# cslr_edmacc_001 register map
Vendor: Texas Instruments
Peripheral module from a debugger description file.
Registers are 32-bit, access not given, reset values left out (the file's numbers can be read two ways) unless marked. A register's access mark holds for its fields unless they carry their own. Offsets are as the file gives them; lines under a group give offsets from that group; [hi:lo] are bit positions; {n}, {i} and the like mark numbered series; 'fields as' and 'values as' point back to an identical list; <NAME> marks a mode.

## EDMACC — Enhanced DMA Channel Controller Module.
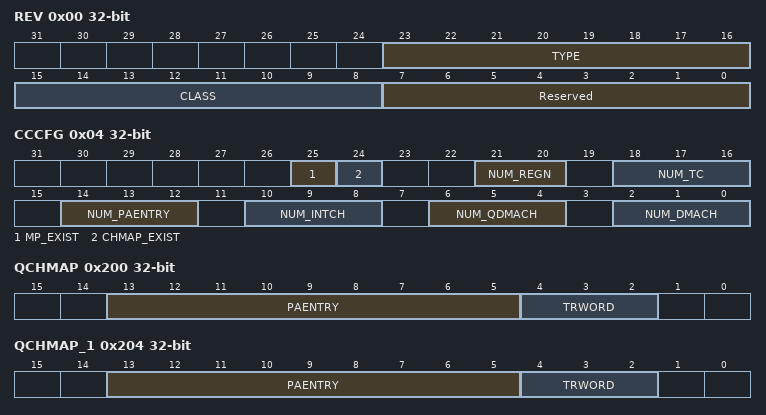
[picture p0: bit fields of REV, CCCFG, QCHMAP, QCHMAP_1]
0x00 REV — Peripheral Revision
  [23:16] TYPE ro — Peripheral Type
  [15:8] CLASS ro — Peripheral Class
  [7:0] Reserved — (access N)
0x04 CCCFG ro — CC Configuration
  [25] MP_EXIST — Memory Protection Existence
    0=None (No Memory protection); 1=INCLUDED (Memory protection logic included)
  [24] CHMAP_EXIST — Channel Mapping Existence
    0=None (No Channel Mapping); 1=INCLUDED (Channel mapping logic included)
  [21:20] NUM_REGN — Number of MP and Shadow regions
    2=4 Regions
  [18:16] NUM_TC — Number of Queues/Number of TCs
    0=1 TC/Event Queue; 1=2 TC/Event Queue
  [14:12] NUM_PAENTRY — Number of PaRAM entries
    3=128 Entries
  [10:8] NUM_INTCH — Number of Interrupt Channels
    1=8 Interrupt Channels; 2=16 Interrupt Channels; 3=32 Interrupt Channels; 4=64 Interrupt Channels
  [6:4] NUM_QDMACH — Number of QDMA Channels
    2=4 QDMA Channels
  [2:0] NUM_DMACH — Number of DMA Channels
    5=64 DMA Channels
0x200 QCHMAP access per field — QDMA Channel Mapping to PaRAM{QCHMAP}
  [13:5] PAENTRY rw — Points to the PaRAM Entry number for the DMA Channel N
  [4:2] TRWORD rw — Points to the specific trigger word of the PaRAM entry defined by PAENTRY
0x204 QCHMAP_1 access per field — QDMA Channel Mapping to PaRAM{QCHMAP}
  fields as QCHMAP
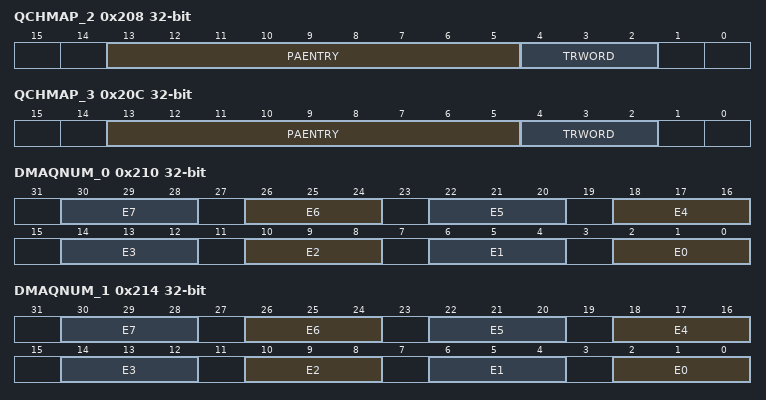
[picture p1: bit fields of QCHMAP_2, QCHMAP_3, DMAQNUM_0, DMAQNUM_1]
0x208 QCHMAP_2 access per field — QDMA Channel Mapping to PaRAM{QCHMAP}
  fields as QCHMAP
0x20C QCHMAP_3 access per field — QDMA Channel Mapping to PaRAM{QCHMAP}
  fields as QCHMAP
0x210 DMAQNUM_0 access per field — DMA Queue Number{DMAQNUM}
  [4n+2:4n] E{n} rw (n=0..7) — Event number = (ArrayIndex * 8) + {n}
0x214 DMAQNUM_1 access per field — DMA Queue Number{DMAQNUM}
  [4n+2:4n] E{n} rw (n=0..7) — Event number = (ArrayIndex * 8) + {n}
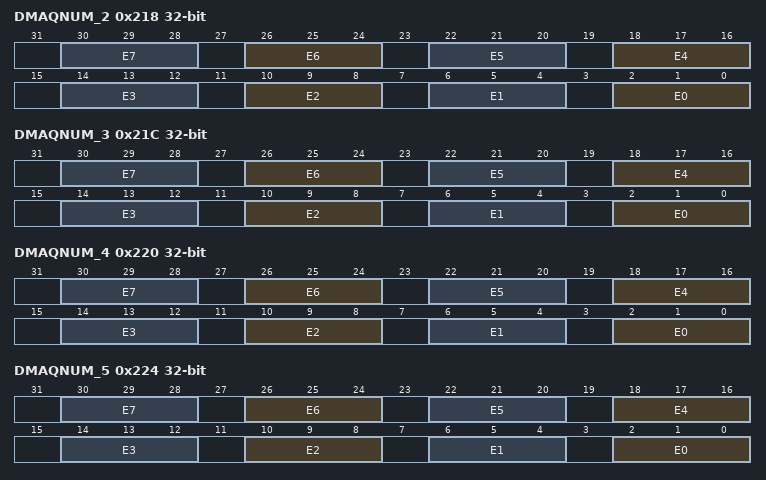
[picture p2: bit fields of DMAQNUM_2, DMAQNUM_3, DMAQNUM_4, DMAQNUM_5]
0x218 DMAQNUM_2 access per field — DMA Queue Number{DMAQNUM}
  [4n+2:4n] E{n} rw (n=0..7) — Event number = (ArrayIndex * 8) + {n}
0x21C DMAQNUM_3 access per field — DMA Queue Number{DMAQNUM}
  [4n+2:4n] E{n} rw (n=0..7) — Event number = (ArrayIndex * 8) + {n}
0x220 DMAQNUM_4 access per field — DMA Queue Number{DMAQNUM}
  [4n+2:4n] E{n} rw (n=0..7) — Event number = (ArrayIndex * 8) + {n}
0x224 DMAQNUM_5 access per field — DMA Queue Number{DMAQNUM}
  [4n+2:4n] E{n} rw (n=0..7) — Event number = (ArrayIndex * 8) + {n}
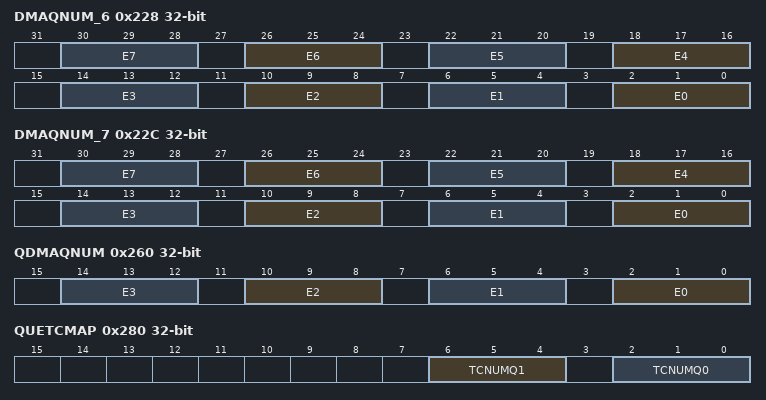
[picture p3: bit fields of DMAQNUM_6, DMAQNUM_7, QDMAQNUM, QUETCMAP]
0x228 DMAQNUM_6 access per field — DMA Queue Number{DMAQNUM}
  [4n+2:4n] E{n} rw (n=0..7) — Event number = (ArrayIndex * 8) + {n}
0x22C DMAQNUM_7 access per field — DMA Queue Number{DMAQNUM}
  [4n+2:4n] E{n} rw (n=0..7) — Event number = (ArrayIndex * 8) + {n}
0x260 QDMAQNUM access per field — QDMA Queue Number
  [4n+2:4n] E{n} rw (n=0..3) — Event number {n}
0x280 QUETCMAP access per field — Queue to TC Mapping
  [6:4] TCNUMQ1 rw — TC Number for Queue 1
  [2:0] TCNUMQ0 rw — TC Number for Queue 0
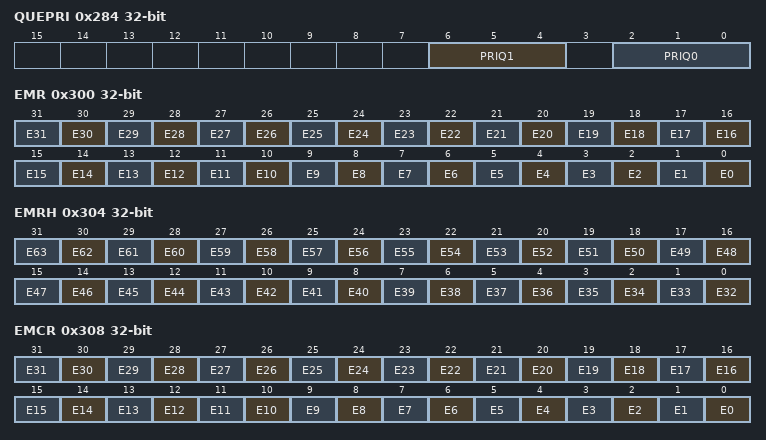
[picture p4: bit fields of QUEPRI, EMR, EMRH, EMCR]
0x284 QUEPRI access per field — Queue Priority
  [6:4] PRIQ1 rw — Priority level for Queue 1
  [2:0] PRIQ0 rw — Priority level for Queue 0
0x300 EMR ro — Event Miss Register
  [n] E{n} (n=0..31) — Event missed number {n}
0x304 EMRH ro — Event Miss Register High
  [n-32] E{n} (n=32..63) — Event missed number {n}
0x308 EMCR ro — Event Miss Clear Register
  [n] E{n} (n=0..31) — Event missed number {n}
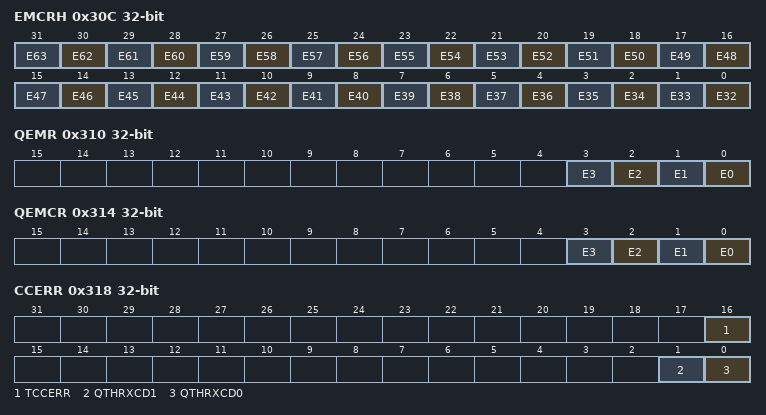
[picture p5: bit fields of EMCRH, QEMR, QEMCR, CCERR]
0x30C EMCRH ro — Event Miss Clear Register High
  [n-32] E{n} (n=32..63) — Event missed number {n}
0x310 QEMR ro — QDMA Event Miss Register
  [n] E{n} (n=0..3) — Event miss event {n}
0x314 QEMCR wo — QDMA Event Miss Register
  [n] E{n} (n=0..3) — Event miss event {n}
0x318 CCERR ro — CC Error Register
  [16] TCCERR — Transfer completion code error
  [1] QTHRXCD1 — Queue Threshold Error for Queue 1
  [0] QTHRXCD0 — Queue Threshold Error for Queue 0
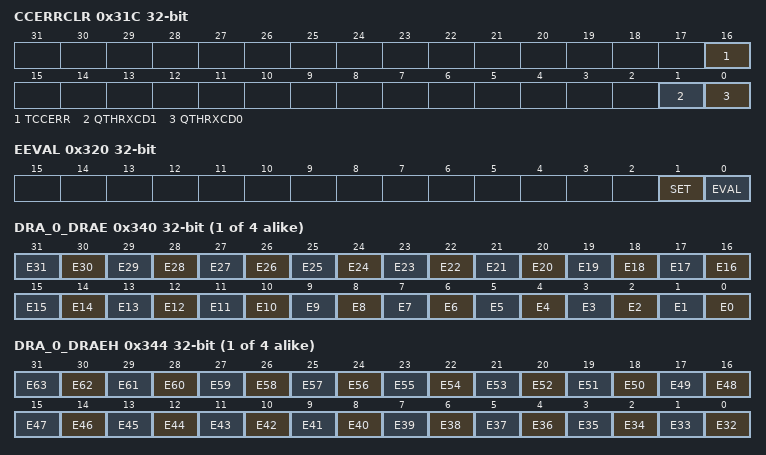
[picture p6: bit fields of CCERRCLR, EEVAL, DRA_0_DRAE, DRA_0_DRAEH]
0x31C CCERRCLR wo — CC Error Clear Register
  fields as CCERR
0x320 EEVAL access per field — Error Evaluation Register
  [1] SET wo — Error interrupt Set
    1=SET (Error Interrupt Set)
  [0] EVAL wo — Error interrupt Evaluate
    1=EVAL (Error Interrupt Evaluate)
{0x340+8i} DRA_{i}_DRAE ro (i=0..3) — DMA Region Access Enable
  [n] E{n} (n=0..31) — Event missed number {n}
{0x344+8i} DRA_{i}_DRAEH ro (i=0..3) — DMA Region Access Enable High
  [n-32] E{n} (n=32..63) — Event missed number {n}
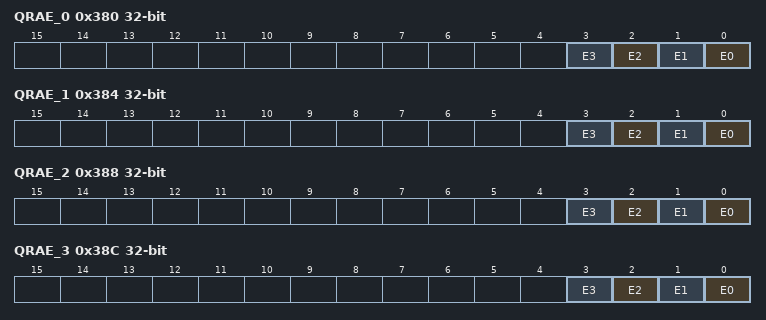
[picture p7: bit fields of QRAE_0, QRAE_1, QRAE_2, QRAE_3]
0x380 QRAE_0 ro — QDMA Region Access Enable{QRAE}
  [n] E{n} (n=0..3) — QDMA Register bit {n}
0x384 QRAE_1 ro — QDMA Region Access Enable{QRAE}
  [n] E{n} (n=0..3) — QDMA Register bit {n}
0x388 QRAE_2 ro — QDMA Region Access Enable{QRAE}
  [n] E{n} (n=0..3) — QDMA Register bit {n}
0x38C QRAE_3 ro — QDMA Region Access Enable{QRAE}
  [n] E{n} (n=0..3) — QDMA Register bit {n}
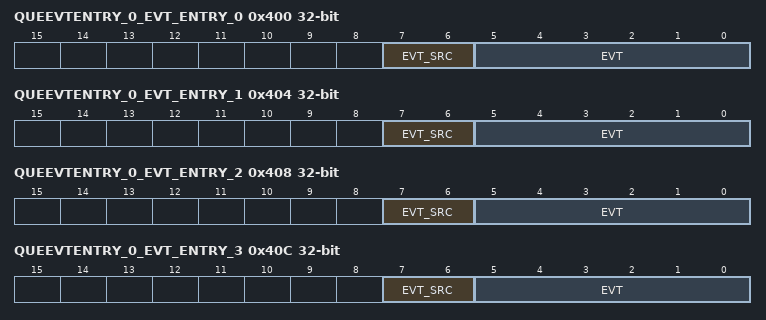
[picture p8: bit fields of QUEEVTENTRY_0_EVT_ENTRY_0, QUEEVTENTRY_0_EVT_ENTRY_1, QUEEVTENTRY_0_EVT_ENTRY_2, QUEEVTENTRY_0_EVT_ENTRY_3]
0x400 QUEEVTENTRY_0_EVT_ENTRY_0 ro — Event Entry{QUEEVTENTRY_0_EVT_ENTRY}
  [7:6] EVT_SRC — Event Source - ER/ESR/CER/QER
  [5:0] EVT — Event
0x404 QUEEVTENTRY_0_EVT_ENTRY_1 ro — Event Entry{QUEEVTENTRY_0_EVT_ENTRY}
  [7:6] EVT_SRC — Event Source - ER/ESR/CER/QER
  [5:0] EVT — Event
0x408 QUEEVTENTRY_0_EVT_ENTRY_2 ro — Event Entry{QUEEVTENTRY_0_EVT_ENTRY}
  [7:6] EVT_SRC — Event Source - ER/ESR/CER/QER
  [5:0] EVT — Event
0x40C QUEEVTENTRY_0_EVT_ENTRY_3 ro — Event Entry{QUEEVTENTRY_0_EVT_ENTRY}
  [7:6] EVT_SRC — Event Source - ER/ESR/CER/QER
  [5:0] EVT — Event
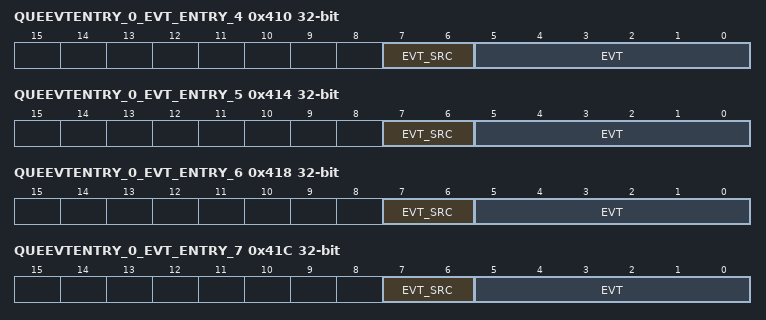
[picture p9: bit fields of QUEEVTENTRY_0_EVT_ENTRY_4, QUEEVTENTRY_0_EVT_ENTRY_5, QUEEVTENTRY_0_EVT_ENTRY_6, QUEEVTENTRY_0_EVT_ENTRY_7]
0x410 QUEEVTENTRY_0_EVT_ENTRY_4 ro — Event Entry{QUEEVTENTRY_0_EVT_ENTRY}
  [7:6] EVT_SRC — Event Source - ER/ESR/CER/QER
  [5:0] EVT — Event
0x414 QUEEVTENTRY_0_EVT_ENTRY_5 ro — Event Entry{QUEEVTENTRY_0_EVT_ENTRY}
  [7:6] EVT_SRC — Event Source - ER/ESR/CER/QER
  [5:0] EVT — Event
0x418 QUEEVTENTRY_0_EVT_ENTRY_6 ro — Event Entry{QUEEVTENTRY_0_EVT_ENTRY}
  [7:6] EVT_SRC — Event Source - ER/ESR/CER/QER
  [5:0] EVT — Event
0x41C QUEEVTENTRY_0_EVT_ENTRY_7 ro — Event Entry{QUEEVTENTRY_0_EVT_ENTRY}
  [7:6] EVT_SRC — Event Source - ER/ESR/CER/QER
  [5:0] EVT — Event
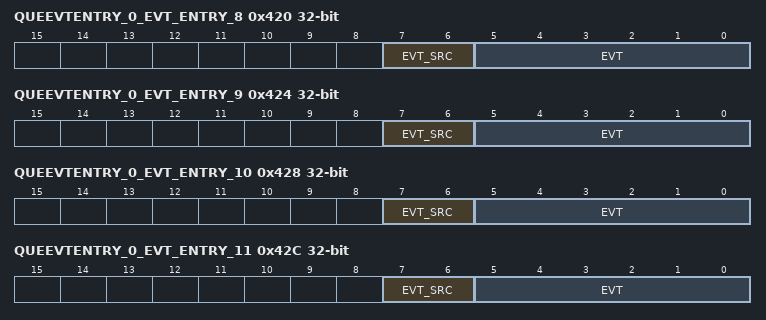
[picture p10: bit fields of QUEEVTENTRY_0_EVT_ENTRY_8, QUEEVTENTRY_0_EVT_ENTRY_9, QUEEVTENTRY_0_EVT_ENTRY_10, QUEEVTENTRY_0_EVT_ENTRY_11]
0x420 QUEEVTENTRY_0_EVT_ENTRY_8 ro — Event Entry{QUEEVTENTRY_0_EVT_ENTRY}
  [7:6] EVT_SRC — Event Source - ER/ESR/CER/QER
  [5:0] EVT — Event
0x424 QUEEVTENTRY_0_EVT_ENTRY_9 ro — Event Entry{QUEEVTENTRY_0_EVT_ENTRY}
  [7:6] EVT_SRC — Event Source - ER/ESR/CER/QER
  [5:0] EVT — Event
0x428 QUEEVTENTRY_0_EVT_ENTRY_10 ro — Event Entry{QUEEVTENTRY_0_EVT_ENTRY}
  [7:6] EVT_SRC — Event Source - ER/ESR/CER/QER
  [5:0] EVT — Event
0x42C QUEEVTENTRY_0_EVT_ENTRY_11 ro — Event Entry{QUEEVTENTRY_0_EVT_ENTRY}
  [7:6] EVT_SRC — Event Source - ER/ESR/CER/QER
  [5:0] EVT — Event
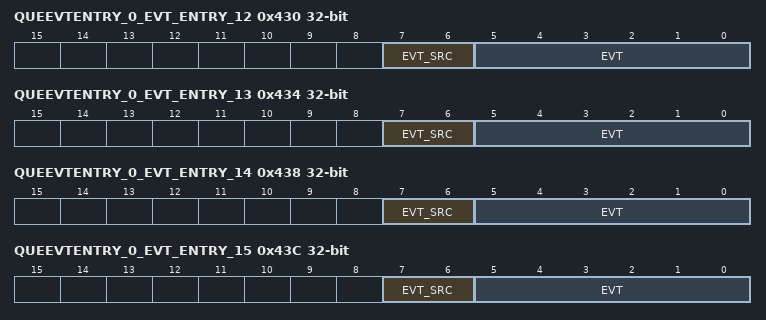
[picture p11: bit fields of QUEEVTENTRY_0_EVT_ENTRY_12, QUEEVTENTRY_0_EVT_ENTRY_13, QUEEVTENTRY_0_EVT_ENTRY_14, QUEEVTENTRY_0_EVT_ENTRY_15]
0x430 QUEEVTENTRY_0_EVT_ENTRY_12 ro — Event Entry{QUEEVTENTRY_0_EVT_ENTRY}
  [7:6] EVT_SRC — Event Source - ER/ESR/CER/QER
  [5:0] EVT — Event
0x434 QUEEVTENTRY_0_EVT_ENTRY_13 ro — Event Entry{QUEEVTENTRY_0_EVT_ENTRY}
  [7:6] EVT_SRC — Event Source - ER/ESR/CER/QER
  [5:0] EVT — Event
0x438 QUEEVTENTRY_0_EVT_ENTRY_14 ro — Event Entry{QUEEVTENTRY_0_EVT_ENTRY}
  [7:6] EVT_SRC — Event Source - ER/ESR/CER/QER
  [5:0] EVT — Event
0x43C QUEEVTENTRY_0_EVT_ENTRY_15 ro — Event Entry{QUEEVTENTRY_0_EVT_ENTRY}
  [7:6] EVT_SRC — Event Source - ER/ESR/CER/QER
  [5:0] EVT — Event
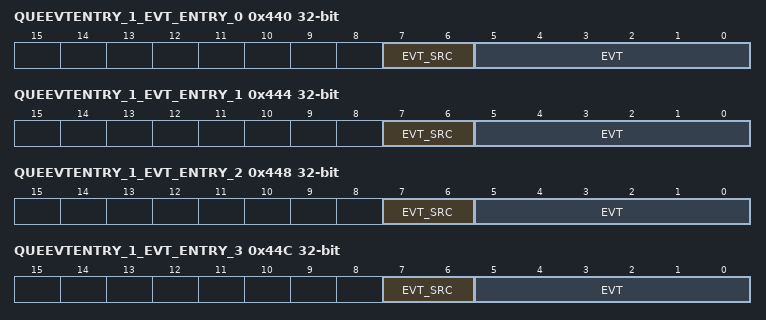
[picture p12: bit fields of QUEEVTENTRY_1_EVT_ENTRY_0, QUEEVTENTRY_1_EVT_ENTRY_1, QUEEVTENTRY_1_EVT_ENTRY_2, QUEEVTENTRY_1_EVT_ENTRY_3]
0x440 QUEEVTENTRY_1_EVT_ENTRY_0 ro — Event Entry{QUEEVTENTRY_1_EVT_ENTRY}
  [7:6] EVT_SRC — Event Source - ER/ESR/CER/QER
  [5:0] EVT — Event
0x444 QUEEVTENTRY_1_EVT_ENTRY_1 ro — Event Entry{QUEEVTENTRY_1_EVT_ENTRY}
  [7:6] EVT_SRC — Event Source - ER/ESR/CER/QER
  [5:0] EVT — Event
0x448 QUEEVTENTRY_1_EVT_ENTRY_2 ro — Event Entry{QUEEVTENTRY_1_EVT_ENTRY}
  [7:6] EVT_SRC — Event Source - ER/ESR/CER/QER
  [5:0] EVT — Event
0x44C QUEEVTENTRY_1_EVT_ENTRY_3 ro — Event Entry{QUEEVTENTRY_1_EVT_ENTRY}
  [7:6] EVT_SRC — Event Source - ER/ESR/CER/QER
  [5:0] EVT — Event
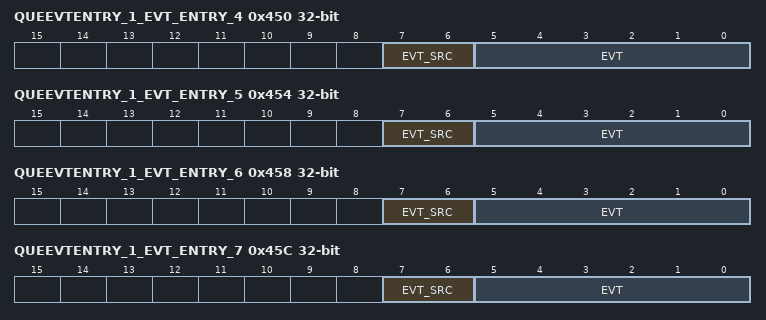
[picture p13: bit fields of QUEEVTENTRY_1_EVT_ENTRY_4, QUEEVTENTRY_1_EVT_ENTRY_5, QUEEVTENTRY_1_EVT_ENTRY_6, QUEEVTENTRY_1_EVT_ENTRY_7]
0x450 QUEEVTENTRY_1_EVT_ENTRY_4 ro — Event Entry{QUEEVTENTRY_1_EVT_ENTRY}
  [7:6] EVT_SRC — Event Source - ER/ESR/CER/QER
  [5:0] EVT — Event
0x454 QUEEVTENTRY_1_EVT_ENTRY_5 ro — Event Entry{QUEEVTENTRY_1_EVT_ENTRY}
  [7:6] EVT_SRC — Event Source - ER/ESR/CER/QER
  [5:0] EVT — Event
0x458 QUEEVTENTRY_1_EVT_ENTRY_6 ro — Event Entry{QUEEVTENTRY_1_EVT_ENTRY}
  [7:6] EVT_SRC — Event Source - ER/ESR/CER/QER
  [5:0] EVT — Event
0x45C QUEEVTENTRY_1_EVT_ENTRY_7 ro — Event Entry{QUEEVTENTRY_1_EVT_ENTRY}
  [7:6] EVT_SRC — Event Source - ER/ESR/CER/QER
  [5:0] EVT — Event
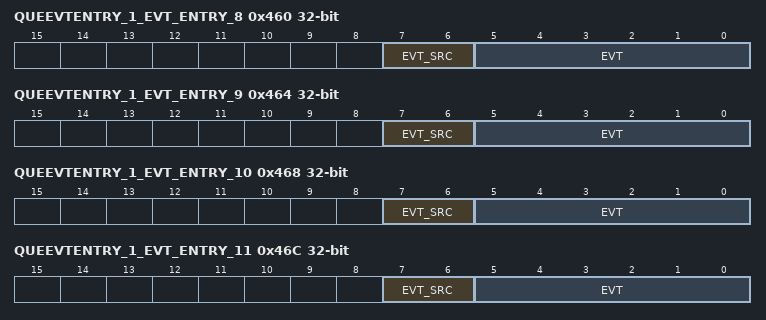
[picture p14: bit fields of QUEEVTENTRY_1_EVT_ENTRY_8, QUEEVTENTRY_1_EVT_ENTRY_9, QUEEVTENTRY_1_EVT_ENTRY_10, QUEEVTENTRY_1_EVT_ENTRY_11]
0x460 QUEEVTENTRY_1_EVT_ENTRY_8 ro — Event Entry{QUEEVTENTRY_1_EVT_ENTRY}
  [7:6] EVT_SRC — Event Source - ER/ESR/CER/QER
  [5:0] EVT — Event
0x464 QUEEVTENTRY_1_EVT_ENTRY_9 ro — Event Entry{QUEEVTENTRY_1_EVT_ENTRY}
  [7:6] EVT_SRC — Event Source - ER/ESR/CER/QER
  [5:0] EVT — Event
0x468 QUEEVTENTRY_1_EVT_ENTRY_10 ro — Event Entry{QUEEVTENTRY_1_EVT_ENTRY}
  [7:6] EVT_SRC — Event Source - ER/ESR/CER/QER
  [5:0] EVT — Event
0x46C QUEEVTENTRY_1_EVT_ENTRY_11 ro — Event Entry{QUEEVTENTRY_1_EVT_ENTRY}
  [7:6] EVT_SRC — Event Source - ER/ESR/CER/QER
  [5:0] EVT — Event
0x470 QUEEVTENTRY_1_EVT_ENTRY_12 ro — Event Entry{QUEEVTENTRY_1_EVT_ENTRY}
  [7:6] EVT_SRC — Event Source - ER/ESR/CER/QER
  [5:0] EVT — Event
0x474 QUEEVTENTRY_1_EVT_ENTRY_13 ro — Event Entry{QUEEVTENTRY_1_EVT_ENTRY}
  [7:6] EVT_SRC — Event Source - ER/ESR/CER/QER
  [5:0] EVT — Event
0x478 QUEEVTENTRY_1_EVT_ENTRY_14 ro — Event Entry{QUEEVTENTRY_1_EVT_ENTRY}
  [7:6] EVT_SRC — Event Source - ER/ESR/CER/QER
  [5:0] EVT — Event
0x47C QUEEVTENTRY_1_EVT_ENTRY_15 ro — Event Entry{QUEEVTENTRY_1_EVT_ENTRY}
  [7:6] EVT_SRC — Event Source - ER/ESR/CER/QER
  [5:0] EVT — Event
0x600 QSTAT_0 — Queue Status{QSTAT}
  [24] THRXD ro — Threshold Exceeded
  [22:21] Reserved — (access N)
  [20:16] WM ro — Watermark for Maximum Queue Usage
  [12:8] NUMVAL ro — Number of Valid Entries in Queue
  [3:0] STRTPTR ro — Start Pointer
0x604 QSTAT_1 — Queue Status{QSTAT}
  fields as QSTAT_0
0x608 QSTAT_2 — Queue Status{QSTAT}
  fields as QSTAT_0
0x60C QSTAT_3 — Queue Status{QSTAT}
  fields as QSTAT_0
0x620 QWMTHRA access per field — Queue Threshold A
  [12:8] Q1 rw — Q1 Threshold
  [4:0] Q0 rw — Q0 Threshold
0x624 QWMTHRB ro — Queue Threshold B
0x640 CCSTAT ro — Channel Controller Status
  [17] QUEACTV1 — Queue 1 Active
    0=NONE; 1=ACTIVE
  [16] QUEACTV0 — Queue 0 Active
    0=NONE; 1=ACTIVE
  [13:8] COMPACT — Completion Request Active
    0=NONE
  [4] ACTV — Channel Controller Active
    0=IDLE; 1=BUSY
  [2] TRACTV — Transfer Request Active
    0=NONE; 1=ACTIVE
  [1] QEVTACTV — QDMA Event Active
    0=NONE; 1=ACTIVE
  [0] EVTACTV — DMA Event Active
    0=NONE; 1=ACTIVE
0x700 AETCTL access per field — Advanced Event Trigger Control
  [31] EN rw — AET Enable
    0=DISABLE; 1=ENABLE
  [13:8] ENDINT rw — AET End Interrupt
  [6] TYPE rw — AET Event Type
    0=DMA; 1=QDMA
  [5:0] STRTEVT rw — AET Start Event
0x704 AETSTAT ro — Advanced Event Trigger Status
  [0] STAT — AET Status
    0=LOW (tpcc_aet is low); 1=HIGH (tpcc_aet is high)
0x708 AETCMD ro — AET Command
  [0] CLR — AET Clear Command
    1=CLEAR (tpc_aet signal clears, AETSTAT.STAT is cleared)
0x1000 ER ro — Event Register
  [n] E{n} (n=0..31) — Event {n}
0x1004 ERH ro — Event Register High
  [n-32] E{n} (n=32..63) — Event {n}
0x1008 ECR wo — Event Clear Register
  [all] fields
    1=CLEAR
  [n] E{n} (n=0..31) — Event {n}
0x100C ECRH wo — Event Clear Register High
  [all] fields
    1=CLEAR
  [n-32] E{n} (n=32..63) — Event {n}
0x1010 ESR wo — Event Set Register
  [all] fields
    1=SET
  [n] E{n} (n=0..31) — Event {n}
0x1014 ESRH wo — Event Set Register High
  [all] fields
    1=SET
  [n-32] E{n} (n=32..63) — Event {n}
0x1018 CER ro — Chained Event Register
  [n] E{n} (n=0..31) — Event {n}
0x101C CERH ro — Chained Event Register High
  [n-32] E{n} (n=32..63) — Event {n}
0x1020 EER ro — Event Enable Register
  [n] E{n} (n=0..31) — Event {n}
0x1024 EERH ro — Event Enable Register High
  [n-32] E{n} (n=32..63) — Event {n}
0x1028 EECR wo — Event Enable Clear Register
  [all] fields
    1=CLEAR
  [n] E{n} (n=0..31) — Event {n}
0x102C EECRH wo — Event Enable Clear Register High
  [all] fields
    1=CLEAR
  [n-32] E{n} (n=32..63) — Event {n}
0x1030 EESR wo — Event Enable Set Register
  [all] fields
    1=SET
  [n] E{n} (n=0..31) — Event {n}
0x1034 EESRH wo — Event Enable Set Register High
  [all] fields
    1=SET
  [n-32] E{n} (n=32..63) — Event {n}
0x1038 SER ro — Secondary Event Register
  [n] E{n} (n=0..31) — Event {n}
0x103C SERH ro — Secondary Event Register High
  [n-32] E{n} (n=32..63) — Event {n}
0x1040 SECR wo — Secondary Event Clear Register
  [all] fields
    1=CLEAR
  [n] E{n} (n=0..31) — Event {n}
0x1044 SECRH wo — Secondary Event Clear Register High
  [all] fields
    1=CLEAR
  [n-32] E{n} (n=32..63) — Event {n}
0x1050 IER ro — Interrupt Enable Register
  [n] I{n} (n=0..31) — Interrupt {n}
0x1054 IERH ro — Interrupt Enable Register High
  [n-32] I{n} (n=32..63) — Interrupt {n}
0x1058 IECR wo — Interrupt Enable Clear Register
  [all] fields
    1=CLEAR
  [n] I{n} (n=0..31) — Interrupt {n}
0x105C IECRH wo — Interrupt Enable Clear Register High
  [all] fields
    1=CLEAR
  [n-32] I{n} (n=32..63) — Interrupt {n}
0x1060 IESR wo — Interrupt Enable Set Register
  [all] fields
    1=SET
  [n] I{n} (n=0..31) — Interrupt {n}
0x1064 IESRH wo — Interrupt Enable Set Register High
  [all] fields
    1=SET
  [n-32] I{n} (n=32..63) — Interrupt {n}
0x1068 IPR ro — Interrupt Pending Register
  [n] I{n} (n=0..31) — Interrupt {n}
0x106C IPRH ro — Interrupt Pending Register High
  [n-32] I{n} (n=32..63) — Interrupt {n}
0x1070 ICR wo — Interrupt Clear Register
  [all] fields
    1=CLEAR
  [n] I{n} (n=0..31) — Interrupt {n}
0x1074 ICRH wo — Interrupt Clear Register High
  [all] fields
    1=CLEAR
  [n-32] I{n} (n=32..63) — Interrupt {n}
0x1078 IEVAL access per field — Interrupt Clear Register High
  [1] SET wo — Interrupt Set
    1=SET (Causes tpcc_intN output to be pulsed is any enabled IERn and IPRn pending)
  [0] EVAL wo — Interrupt Evaluate
    1=EVAL (Causes tpcc_intN output to be pulsed is any enabled IERn and IPRn pending)
0x1080 QER ro — QDMA Event Register
  [n] E{n} (n=0..3) — Event {n}
0x1084 QEER ro — QDMA Event Enable Register
  [n] E{n} (n=0..3) — Event {n}
0x1088 QEECR ro — QDMA Event Enable Clear Register
  [all] fields
    1=CLEAR
  [n] E{n} (n=0..3) — Event {n}
0x108C QEESR ro — QDMA Event Enable Set Register
  [all] fields
    1=SET
  [n] E{n} (n=0..3) — Event {n}
0x1090 QSER ro — QDMA Secondary Event Register
  [n] E{n} (n=0..3) — Event {n}
0x1094 QSECR ro — QDMA Secondary Event Clear Register
  [all] fields
    1=CLEAR
  [n] E{n} (n=0..3) — Event {n}
{0x2000+0x200*i} SHADOW_{i}_ER (i=0..3) — Event Register
  [31:0] REG
{0x2004+0x200*i} SHADOW_{i}_ERH (i=0..3) — Event Register High
  [31:0] REG
{0x2008+0x200*i} SHADOW_{i}_ECR (i=0..3) — Event Clear Register
  [31:0] REG
{0x200C+0x200*i} SHADOW_{i}_ECRH (i=0..3) — Event Clear Register High
  [31:0] REG
{0x2010+0x200*i} SHADOW_{i}_ESR (i=0..3) — Event Set Register
  [31:0] REG
{0x2014+0x200*i} SHADOW_{i}_ESRH (i=0..3) — Event Set Register High
  [31:0] REG
{0x2018+0x200*i} SHADOW_{i}_CER (i=0..3) — Chained Event Register
  [31:0] REG
{0x201C+0x200*i} SHADOW_{i}_CERH (i=0..3) — Chained Event Register High
  [31:0] REG
{0x2020+0x200*i} SHADOW_{i}_EER (i=0..3) — Event Enable Register
  [31:0] REG
{0x2024+0x200*i} SHADOW_{i}_EERH (i=0..3) — Event Enable Register High
  [31:0] REG
{0x2028+0x200*i} SHADOW_{i}_EECR (i=0..3) — Event Enable Clear Register
  [31:0] REG
{0x202C+0x200*i} SHADOW_{i}_EECRH (i=0..3) — Event Enable Clear Register High
  [31:0] REG
{0x2030+0x200*i} SHADOW_{i}_EESR (i=0..3) — Event Enable Set Register
  [31:0] REG
{0x2034+0x200*i} SHADOW_{i}_EESRH (i=0..3) — Event Enable Set Register High
  [31:0] REG
{0x2038+0x200*i} SHADOW_{i}_SER (i=0..3) — Secondary Event Register
  [31:0] REG
{0x203C+0x200*i} SHADOW_{i}_SERH (i=0..3) — Secondary Event Register High
  [31:0] REG
{0x2040+0x200*i} SHADOW_{i}_SECR (i=0..3) — Secondary Event Clear Register
  [31:0] REG
{0x2044+0x200*i} SHADOW_{i}_SECRH (i=0..3) — Secondary Event Clear Register High
  [31:0] REG
{0x2050+0x200*i} SHADOW_{i}_IER (i=0..3) — Interrupt Enable Register
  [31:0] REG
{0x2054+0x200*i} SHADOW_{i}_IERH (i=0..3) — Interrupt Enable Register High
  [31:0] REG
{0x2058+0x200*i} SHADOW_{i}_IECR (i=0..3) — Interrupt Enable Clear Register
  [31:0] REG
{0x205C+0x200*i} SHADOW_{i}_IECRH (i=0..3) — Interrupt Enable Clear Register High
  [31:0] REG
{0x2060+0x200*i} SHADOW_{i}_IESR (i=0..3) — Interrupt Enable Set Register
  [31:0] REG
{0x2064+0x200*i} SHADOW_{i}_IESRH (i=0..3) — Interrupt Enable Set Register High
  [31:0] REG
{0x2068+0x200*i} SHADOW_{i}_IPR (i=0..3) — Interrupt Pending Register
  [31:0] REG
{0x206C+0x200*i} SHADOW_{i}_IPRH (i=0..3) — Interrupt Pending Register High
  [31:0] REG
{0x2070+0x200*i} SHADOW_{i}_ICR (i=0..3) — Interrupt Clear Register
  [31:0] REG
{0x2074+0x200*i} SHADOW_{i}_ICRH (i=0..3) — Interrupt Clear Register High
  [31:0] REG
{0x2078+0x200*i} SHADOW_{i}_IEVAL (i=0..3) — Interrupt Clear Register High
  [31:0] REG
{0x2080+0x200*i} SHADOW_{i}_QER (i=0..3) — QDMA Event Register
  [31:0] REG
{0x2084+0x200*i} SHADOW_{i}_QEER (i=0..3) — QDMA Event Enable Register
  [31:0] REG
{0x2088+0x200*i} SHADOW_{i}_QEECR (i=0..3) — QDMA Event Enable Clear Register
  [31:0] REG
{0x208C+0x200*i} SHADOW_{i}_QEESR (i=0..3) — QDMA Event Enable Set Register
  [31:0] REG
{0x2090+0x200*i} SHADOW_{i}_QSER (i=0..3) — QDMA Secondary Event Register
  [31:0] REG
{0x2094+0x200*i} SHADOW_{i}_QSECR (i=0..3) — QDMA Secondary Event Clear Register
  [31:0] REG
